# STM32MP21_CA35 register map
File version: 0.4
CPU: CM33 r0p1, little endian, MPU, FPU, vendor SysTick, 8 interrupt priority bits
Registers are 32-bit, read-write, reset 0x0 unless marked. A register's access mark holds for its fields unless they carry their own. Offsets are from the block's base; [hi:lo] are bit positions; {n}, {i} and the like mark numbered series; 'fields as' and 'values as' point back to an identical list.

## HPDMA1 — HPDMA register block
Base 0x40400000
Same registers: HPDMA2 0x40410000, HPDMA3 0x40420000, HPDMA1_S 0x50400000, HPDMA2_S 0x50410000, HPDMA3_S 0x50420000
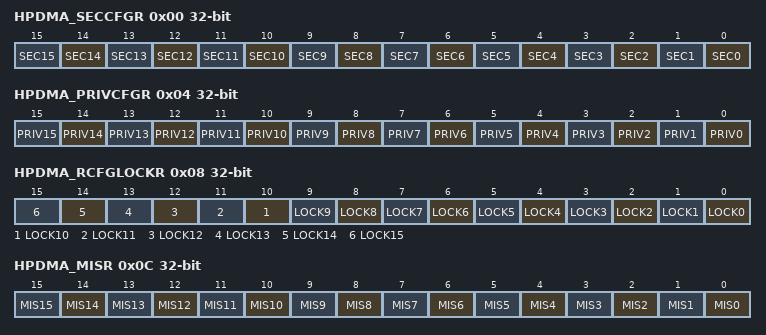
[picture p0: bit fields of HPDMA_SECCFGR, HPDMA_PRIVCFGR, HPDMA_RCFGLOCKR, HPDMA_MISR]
0x00 HPDMA_SECCFGR — HPDMA secure configuration register
  [all] fields
    0=Nonsecure; 1=Secure
  [n] SEC{n} (n=0..15) — Secure state of channel x
0x04 HPDMA_PRIVCFGR — HPDMA privileged configuration register
  [all] fields
    0=Unprivileged; 1=Privileged
  [n] PRIV{n} (n=0..15) — Privileged state of channel x
0x08 HPDMA_RCFGLOCKR — HPDMA configuration lock register
  [all] fields
    0=Secure privilege and CID configuration of the channel x is writable; 1=Secure privilege and CID configuration of the channel x is not writable
  [n] LOCK{n} (n=0..15) — Lock of the configuration of HPDMA_SECCFGR.
0x0C HPDMA_MISR ro — HPDMA nonsecure masked interrupt status register
  [all] fields
    0=No interrupt occurred on channel x; 1=An interrupt occurred on channel x
  [n] MIS{n} (n=0..15) — Masked interrupt status of channel x
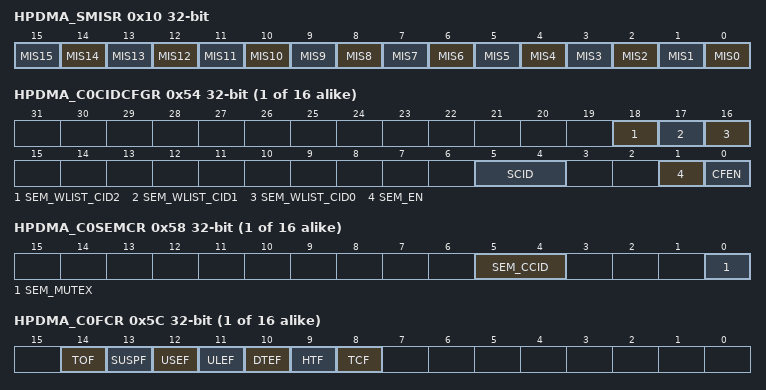
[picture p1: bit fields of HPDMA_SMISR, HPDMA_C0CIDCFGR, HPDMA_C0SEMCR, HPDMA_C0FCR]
0x10 HPDMA_SMISR ro — HPDMA secure masked interrupt status register
  [all] fields
    0=No interrupt occurred on the secure channel x; 1=An interrupt occurred on the secure channel x
  [n] MIS{n} (n=0..15) — Masked interrupt status of the secure channel x
{0x50+0x80*i} HPDMA_C{i}LBAR (i=0..15) — HPDMA channel {i} linked-list base address register
  [31:16] LBA — Linked-list base address of HPDMA channel x
{0x54+0x80*i} HPDMA_C{i}CIDCFGR (i=0..15) — HPDMA channel {i} CID register
  [18] SEM_WLIST_CID2 — White-listed CID2 in the CID allocation pool (for when the channel x
    0=CID2 black-listed in the semaphore-based CID allocation pool; 1=CID2 white-listed in the semaphore-based CID allocation pool
  [17] SEM_WLIST_CID1 — White-listed CID1 in the CID allocation pool (for when the channel x
    0=CID1 black-listed in the semaphore-based CID allocation pool; 1=CID1 white-listed in the semaphore-based CID allocation pool
  [16] SEM_WLIST_CID0 — White-listed CID0 in the CID allocation pool (for when the channel x
    0=CID0 black-listed in the semaphore-based CID allocation pool; 1=CID0 white-listed in the semaphore-based CID allocation pool
  [5:4] SCID — Allocation of a static/single CID to the channel x (for when the channel x CID configuration is not in semaphore mode)
    0=CID0 allocated to the channel x; 1=CID1 allocated to the channel x; 2=CID2 allocated to the channel x
  [1] SEM_EN — Semaphore mode enable (for the CID allocation policy to the channel x)
    0=Semaphore mode disabled; 1=Semaphore mode enabled
  [0] CFEN — CID filtering enable of the channel x
    0=CID filtering disabled for when accessing a channel x register/bit field; 1=CID filtering enabled for when accessing a channel x register/bit field
{0x58+0x80*i} HPDMA_C{i}SEMCR (i=0..15) — HPDMA channel {i} semaphore control register
  [5:4] SEM_CCID ro — Current CID allocated to the channel x (in semaphore mode)
    0=CID0 is the last white-listed CID that took the control of the channel x; 1=CID1 is the last white-listed CID that took the control of the channel x; 2=CID2 is the last white-listed CID that took the control of the channel x
  [0] SEM_MUTEX — Mutual exclusion semaphore for the CID allocation of the channel x
    0=B_0x0_WRITE (Release the control of the channel x (in semaphore mode) to any white-listed CID.); 1=B_0x1_WRITE (Take the control of the channel x (in semaphore mode), from one of the white-listed)
{0x5C+0x80*i} HPDMA_C{i}FCR wo (i=0..15) — HPDMA channel {i} flag clear register
  [14] TOF — Trigger overrun flag clear
    0=No effect; 1=Corresponding TOF flag cleared
  [13] SUSPF — Completed suspension flag clear
    0=No effect; 1=Corresponding SUSPF flag cleared
  [12] USEF — User setting error flag clear
    0=No effect; 1=Corresponding USEF flag cleared
  [11] ULEF — Update link transfer error flag clear
    0=No effect; 1=Corresponding ULEF flag cleared
  [10] DTEF — Data transfer error flag clear
    0=No effect; 1=Corresponding DTEF flag cleared
  [9] HTF — Half transfer flag clear
    0=No effect; 1=Corresponding HTF flag cleared
  [8] TCF — Transfer complete flag clear
    0=No effect; 1=Corresponding TCF flag cleared
{0x60+0x80*i} HPDMA_C{i}SR ro reset 0x1 (i=0..15) — HPDMA channel {i} status register
  [24:16] FIFOL
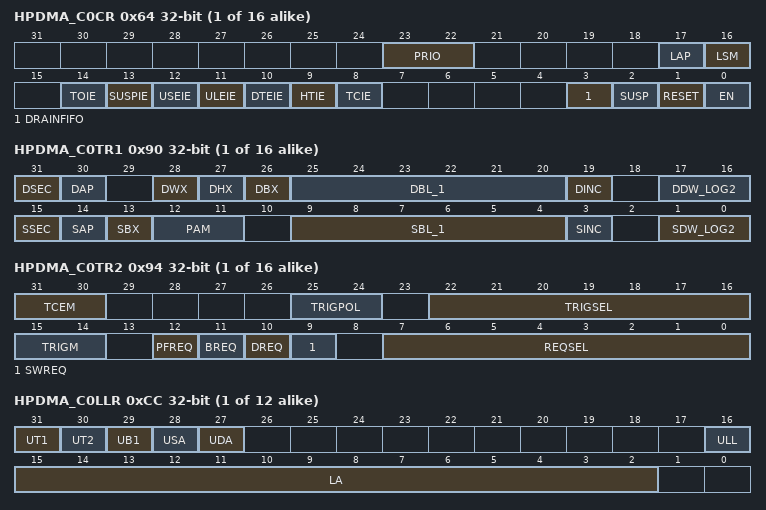
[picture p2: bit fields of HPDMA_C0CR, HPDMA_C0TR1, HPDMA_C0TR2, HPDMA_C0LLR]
{0x64+0x80*i} HPDMA_C{i}CR (i=0..15) — HPDMA channel {i} control register
  [23:22] PRIO — Priority level of the channel x HPDMA transfer versus others
    0=Low priority, low weight; 1=Low priority, mid weight; 2=Low priority, high weight; 3=High priority
  [17] LAP — lLnked-list allocated port
    0=Port 0 (AXI) allocated; 1=Port 1 (AHB) allocated
  [16] LSM — Link step mode
    0=Channel executed for the full linked-list and completed at the end of the last LLI (HPDMA_CxLLR = 0); 1=Channel executed once for the current LLI
  [14] TOIE — Trigger overrun interrupt enable
    0=Interrupt disabled; 1=Interrupt enabled
  [13] SUSPIE — cCmpleted suspension interrupt enable
    0=Interrupt disabled; 1=Interrupt enabled
  [12] USEIE — User setting error interrupt enable
    0=Interrupt disabled; 1=Interrupt enabled
  [11] ULEIE — Update link transfer error interrupt enable
    0=Interrupt disabled; 1=Interrupt enabled
  [10] DTEIE — Data transfer error interrupt enable
    0=Interrupt disabled; 1=Interrupt enabled
  [9] HTIE — Half transfer complete interrupt enable
    0=Interrupt disabled; 1=Interrupt enabled
  [8] TCIE — Transfer complete interrupt enable
    0=Interrupt disabled; 1=Interrupt enabled
  [3] DRAINFIFO wo — Empty FIFO
    0=Write: no action; 1=Write: drain FIFO after having suspended the channel
  [2] SUSP — Suspend
    0=Write: resume channel, read: channel not suspended; 1=Write: suspend channel, read: channel suspended
  [1] RESET wo
    0=No channel reset; 1=Channel reset
  [0] EN — Enable
    0=Write: ignored, read: channel disabled; 1=Write: enable channel, read: channel enabled
{0x90+0x80*i} HPDMA_C{i}TR1 (i=0..15) — HPDMA channel {i} transfer register 1
  [31] DSEC — Security attribute of the HPDMA transfer to the destination
    0=HPDMA transfer nonsecure; 1=HPDMA transfer secure
  [30] DAP — Destination allocated port
    0=Port 0 (AXI) allocated; 1=Port 1 (AHB) allocated
  [28] DWX — Destination word exchange
    0=No word-based exchanged within double-word; 1=The two consecutive (post PAM) words are exchanged in each destination double-word
  [27] DHX — Destination half-word exchange
    0=No half-word-based exchanged within word; 1=The two consecutive (post PAM) half-words are exchanged in each destination word
  [26] DBX — Destination byte exchange
    0=No byte-based exchange within half-word; 1=The two consecutive (post PAM) bytes are exchanged in each destination half-word
  [25:20] DBL_1 — Destination burst length minus 1, between 0 and 63
  [19] DINC — Destination incrementing burst
    0=Fixed burst; 1=Contiguously incremented burst
  [17:16] DDW_LOG2 — Binary logarithm of the destination data width of a burst, in bytes
    0=Byte; 1=Half-word (2 bytes); 2=Word (4 bytes); 3=If DAP = 0 (AXI), double-word (8 bytes)
  [15] SSEC — Security attribute of the HPDMA transfer from the source
    0=HPDMA transfer nonsecure; 1=HPDMA transfer secure
  [14] SAP — Source allocated port
    0=Port 0 (AXI) allocated; 1=Port 1 (AHB) allocated
  [13] SBX — Source byte exchange within the unaligned half-word of each source word
    0=No byte-based exchange within the unaligned half-word of each source word; 1=The two consecutive bytes within the unaligned half-word of each source word
  [12:11] PAM — Padding/alignment mode
    0=B_0x0_PAM_1 (Source data is transferred as right aligned, padded with 0s up to the destination data width); 1=B_0x1_PAM_1 (Source data is transferred as right aligned, sign extended up to the destination data width); 2=B_0x2_PAM_1 (Successive source data are FIFO queued and packed at the destination data width, in a left (LSB) to right (MSB) order (named little endian), before a destination transfer); 3=B_0x3_PAM_1 (Successive source data are FIFO queued and packed at the destination data width, in a left (LSB) to right (MSB) order (named little endian), before a destination transfer)
  [9:4] SBL_1 — Source burst length minus 1, between 0 and 63
  [3] SINC — Source incrementing burst
    0=Fixed burst; 1=Contiguously incremented burst
  [1:0] SDW_LOG2 — Binary logarithm of the source data width of a burst in bytes
    0=Byte; 1=Half-word (2 bytes); 2=Word (4 bytes); 3=If SAP = 0 (AXI), double-word (8 bytes)
{0x94+0x80*i} HPDMA_C{i}TR2 (i=0..15) — HPDMA channel {i} transfer register 2
  [31:30] TCEM — Transfer complete event mode
    0=At block level (when HPDMA_CxBR1; 1=Channel x = 0 to 11, same as 00; channel x = 12 to 15, at 2D/repeated block level; 2=At LLI level: The complete transfer event is generated at the end of the LLI transfer, including the update of the LLI if any; 3=At channel level: The complete transfer event is generated at the end of the last LLI transfer
  [25:24] TRIGPOL — Trigger event polarity
    0=No trigger (masked trigger event); 1=Trigger on the rising edge; 2=Trigger on the falling edge; 3=Same as 00
  [22:16] TRIGSEL — Trigger event input selection
  [15:14] TRIGM — Trigger mode
    0=at block level: the first burst read of each block transfer is conditioned by one hit trigger (channel x = 12 to 15, for each block if a 2D/repeated block is configured with HPDMA_CxBR1; 1=channel x = 0 to 11, same as 00; channel x = 12 to 15, at 2D/repeated block level, the first burst read of a 2D/repeated block transfer is conditioned by one hit trigger; 2=at link level: a LLI link transfer is conditioned by one hit trigger; 3=at programmed burst level: If SWREQ = 1, each programmed burst read is conditioned by one hit trigger
  [12] PFREQ — Hardware request in peripheral flow control mode
    0=The selected hardware request is driven by a peripheral with a hardware request/acknowledge protocol in HPDMA control mode; 1=The selected hardware request is driven by a peripheral with a hardware request/acknowledge protocol in peripheral control mode
  [11] BREQ — Block hardware request
    0=The selected hardware request is driven by a peripheral with a hardware request/acknowledge protocol at a burst level; 1=The selected hardware request is driven by a peripheral with a hardware request/acknowledge protocol at a block level (see Section26
  [10] DREQ — Destination hardware request
    0=Selected hardware request driven by a source peripheral (request signal taken into account by the HPDMA transfer scheduler over the source/read port); 1=Selected hardware request driven by a destination peripheral (request signal taken into account by the HPDMA transfer scheduler over the destination/write port)
  [9] SWREQ — Software request
    0=No software request; 1=Software request for a memory-to-memory transfer
  [7:0] REQSEL — Hardware request selection
{0x98+0x80*i} HPDMA_C{i}BR1 (i=0..11) — HPDMA channel {i} block register 1
  [15:0] BNDT — Block number of data bytes to transfer from the source
{0x9C+0x80*i} HPDMA_C{i}SAR (i=0..15) — HPDMA channel {i} source address register
  [31:0] SA — Source address
{0xA0+0x80*i} HPDMA_C{i}DAR (i=0..15) — HPDMA channel {i} destination address register
  [31:0] DA — destination address
{0xCC+0x80*i} HPDMA_C{i}LLR (i=0..11) — HPDMA channel {i} linked-list address register
  [31] UT1 — Update HPDMA_CxTR1 from memory
    0=No HPDMA_CxTR1 update; 1=HPDMA_CxTR1 update
  [30] UT2 — Update HPDMA_CxTR2 from memory
    0=No HPDMA_CxTR2 update; 1=HPDMA_CxTR2 update
  [29] UB1 — Update HPDMA_CxBR1 from memory
    0=No HPDMA_CxBR1 update from memory (HPDMA_CxBR1; 1=HPDMA_CxBR1 update
  [28] USA — Update HPDMA_CxSAR from memory
    0=No HPDMA_CxSAR update; 1=HPDMA_CxSAR update
  [27] UDA — Update HPDMA_CxDAR register from memory
    0=No HPDMA_CxDAR update; 1=HPDMA_CxDAR update
  [16] ULL — Update HPDMA_CxLLR register from memory
    0=No HPDMA_CxLLR update; 1=HPDMA_CxLLR update
  [15:2] LA — Pointer (16-bit low-significant address) to the next linked-list data structure
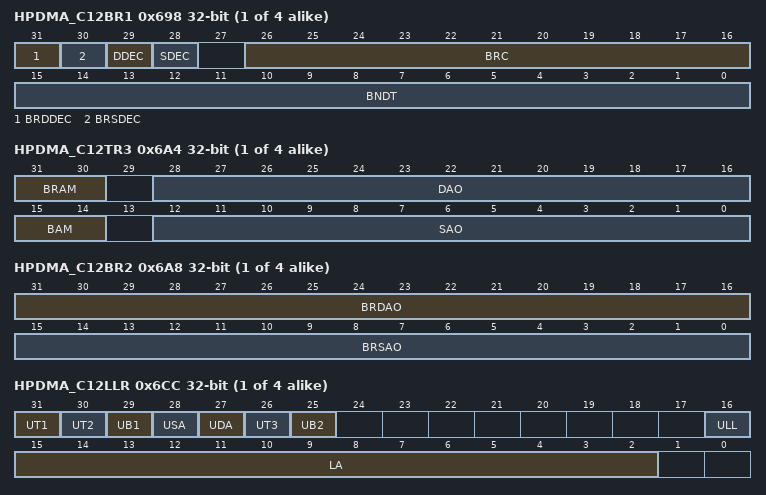
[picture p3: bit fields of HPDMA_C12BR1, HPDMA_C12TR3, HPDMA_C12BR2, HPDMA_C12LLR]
{0x98+0x80*i} HPDMA_C{i}BR1 (i=12..15) — HPDMA channel {i} alternate block register 1
  [31] BRDDEC — Block repeat destination address decrement
    0=At the end of a block transfer, the HPDMA_CxDAR register is updated by adding the programmed offset HPDMA_CxBR2; 1=At the end of a block transfer, the HPDMA_CxDAR register is updated by subtracting the programmed offset HPDMA_CxBR2
  [30] BRSDEC — Block repeat source address decrement
    0=At the end of a block transfer, the HPDMA_CxSAR register is updated by adding the programmed offset HPDMA_CxBR2; 1=At the end of a block transfer, the HPDMA_CxSAR register is updated by subtracting the programmed offset HPDMA_CxBR2
  [29] DDEC — destination address decrement
    0=At the end of a programmed burst transfer to the destination, the HPDMA_CxDAR register is updated by adding the programmed offset HPDMA_CxTR3; 1=At the end of a programmed burst transfer to the destination, the HPDMA_CxDAR register is updated by subtracting the programmed offset HPDMA_CxTR3
  [28] SDEC — source address decrement
    0=At the end of a programmed burst transfer from the source, the HPDMA_CxSAR register is updated by adding the programmed offset HPDMA_CxTR3; 1=At the end of a programmed burst transfer from the source, the HPDMA_CxSAR register is updated by subtracting the programmed offset HPDMA_CxTR3
  [26:16] BRC — Block repeat counter
  [15:0] BNDT — Block number of data bytes to transfer from the source
{0xA4+0x80*i} HPDMA_C{i}TR3 (i=12..15) — HPDMA channel {i} transfer register 3
  [31:30] BRAM — Block repeated alignment mode
    {v}=Repeated block address offset (HPDMA_CxBR2 (v=0..3)
  [28:16] DAO — Destination address offset increment
  [15:14] BAM — Block alignment mode
    0=Block address offset (HPDMA_CxTR3; 1=block address offset (HPDMA_CxTR3; 2=Block address offset (HPDMA_CxTR3; 3=Block address offset (HPDMA_CxTR3
  [12:0] SAO — Source address offset increment
{0xA8+0x80*i} HPDMA_C{i}BR2 (i=12..15) — HPDMA channel {i} block register 2
  [31:16] BRDAO — Block repeated destination address offset
  [15:0] BRSAO — Block repeated source address offset
{0xCC+0x80*i} HPDMA_C{i}LLR (i=12..15) — HPDMA channel {i} alternate linked-list address register
  [31] UT1 — Update HPDMA_CxTR1 from memory
    0=No HPDMA_CxTR1 update; 1=HPDMA_CxTR1 update
  [30] UT2 — Update HPDMA_CxTR2 from memory
    0=No HPDMA_CxTR2 update; 1=HPDMA_CxTR2 update
  [29] UB1 — Update HPDMA_CxBR1 from memory
    values as HPDMA_C0LLR.UB1
  [28] USA — Update HPDMA_CxSAR from memory
    0=No HPDMA_CxSAR update; 1=HPDMA_CxSAR update
  [27] UDA — Update HPDMA_CxDAR register from memory
    0=No HPDMA_CxDAR update; 1=HPDMA_CxDAR update
  [26] UT3 — Update HPDMA_CxTR3 from memory
    0=No HPDMA_CxTR3 update; 1=HPDMA_CxTR3 update
  [25] UB2 — Update HPDMA_CxBR2 from memory
    0=No HPDMA_CxBR2 update; 1=HPDMA_CxBR2 update
  [16] ULL — Update HPDMA_CxLLR register from memory
    0=No HPDMA_CxLLR update; 1=HPDMA_CxLLR update
  [15:2] LA — Pointer (16-bit low-significant address) to the next linked-list data structure
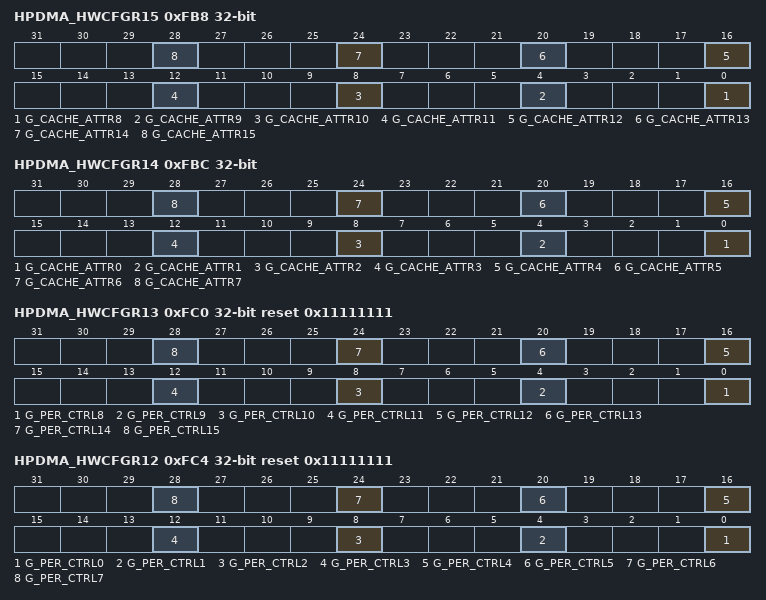
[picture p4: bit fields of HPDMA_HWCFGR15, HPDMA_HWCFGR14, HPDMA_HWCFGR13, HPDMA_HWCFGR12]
0xFB8 HPDMA_HWCFGR15 ro — HPDMA hardware configuration 15 register
  [all] fields
    0=Cache attributes not supported; 1=Cache attributes supported
  [4n-32] G_CACHE_ATTR{n} (n=8..15) — CACHE attributes support for CHANNEL {n}
0xFBC HPDMA_HWCFGR14 ro — HPDMA hardware configuration 14 register
  [all] fields
    values as the fields of HPDMA_HWCFGR15
  [4n] G_CACHE_ATTR{n} (n=0..7) — CACHE attributes support for CHANNEL {n}
0xFC0 HPDMA_HWCFGR13 ro reset 0x11111111 — HPDMA hardware configuration 13 register
  [all] fields
    0=No peripheral flow control mode; 1=Peripheral flow control mode allowed
  [4n-32] G_PER_CTRL{n} (n=8..15) — DMA transfer type for channel {n}
0xFC4 HPDMA_HWCFGR12 ro reset 0x11111111 — HPDMA hardware configuration 12 register
  [all] fields
    values as the fields of HPDMA_HWCFGR13
  [4n] G_PER_CTRL{n} (n=0..7) — DMA transfer type for channel {n}
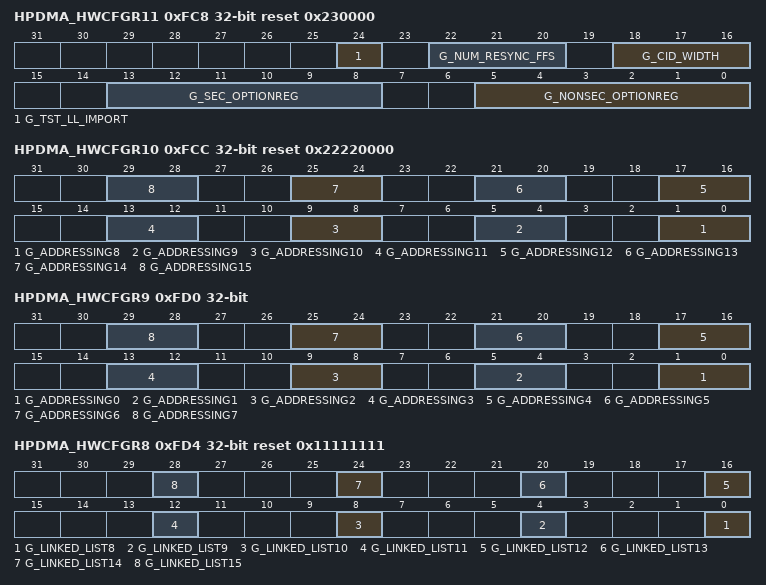
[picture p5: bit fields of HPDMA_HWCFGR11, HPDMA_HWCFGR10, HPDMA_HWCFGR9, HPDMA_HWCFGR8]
0xFC8 HPDMA_HWCFGR11 ro reset 0x230000 — HPDMA hardware configuration 11 register
  [24] G_TST_LL_IMPORT — Master port for the link transfer (DFT purpose only)
    0=Port 0; 1=Port 1
  [22:20] G_NUM_RESYNC_FFS — Number of resynchronization flip-flops, in the range 2 to 6
  [18:16] G_CID_WIDTH — CID bus width, in the range 1 to 4
  [13:8] G_SEC_OPTIONREG — Secure optional register width, in the range 0 to 32
    0=No register
  [5:0] G_NONSEC_OPTIONREG — nonsecure optional register width, in the range 0 to 32
    0=No register
0xFCC HPDMA_HWCFGR10 ro reset 0x22220000 — HPDMA hardware configuration 10 register
  [all] fields
    0=Fixed/contiguous block addressing; 1=Programmable 2D addressing
  [4n-31:4n-32] G_ADDRESSING{n} (n=8..15) — DMA transfer type for channel {n}
0xFD0 HPDMA_HWCFGR9 ro — HPDMA hardware configuration 9 register
  [all] fields
    values as the fields of HPDMA_HWCFGR10
  [4n+1:4n] G_ADDRESSING{n} (n=0..7) — DMA transfer type for channel {n}
0xFD4 HPDMA_HWCFGR8 ro reset 0x11111111 — HPDMA hardware configuration 8 register
  [all] fields
    0=No linked-list mode; 1=Linked-list mode allowed
  [4n-32] G_LINKED_LIST{n} (n=8..15) — DMA transfer type for channel {n}
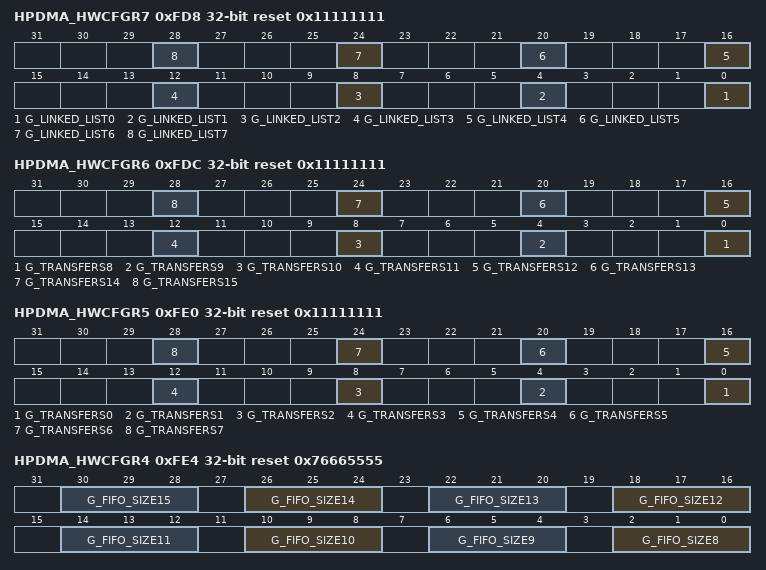
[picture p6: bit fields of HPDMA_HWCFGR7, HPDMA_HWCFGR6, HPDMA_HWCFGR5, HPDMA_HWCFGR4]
0xFD8 HPDMA_HWCFGR7 ro reset 0x11111111 — HPDMA hardware configuration 7 register
  [all] fields
    0=No linked-list mode; 1=Linked-list mode allowed
  [4n] G_LINKED_LIST{n} (n=0..7) — DMA transfer type for channel {n}
0xFDC HPDMA_HWCFGR6 ro reset 0x11111111 — HPDMA hardware configuration 6 register
  [all] fields
    0=Single only; 1=Burst and single
  [4n-32] G_TRANSFERS{n} (n=8..15) — DMA transfer type for channel {n}
0xFE0 HPDMA_HWCFGR5 ro reset 0x11111111 — HPDMA hardware configuration 5 register
  [all] fields
    0=Single only; 1=Burst and single
  [4n] G_TRANSFERS{n} (n=0..7) — DMA transfer type for channel {n}
0xFE4 HPDMA_HWCFGR4 ro reset 0x76665555 — HPDMA hardware configuration 4 register
  [all] fields
    0=No FIFO
  [4n-30:4n-32] G_FIFO_SIZE{n} (n=8..15) — FIFO size for the channel {n}, in the range 0 to 7
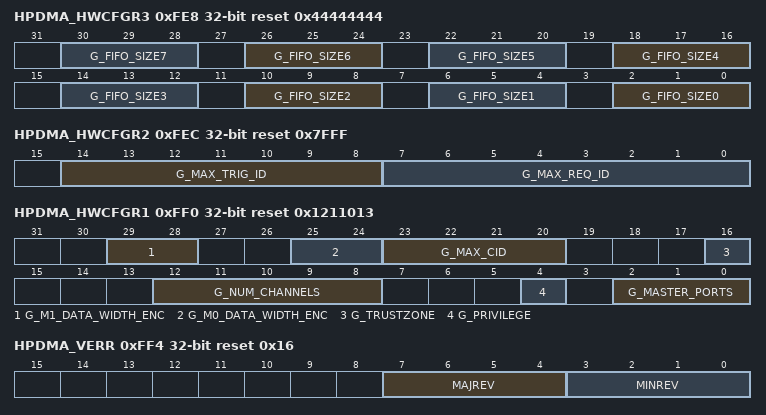
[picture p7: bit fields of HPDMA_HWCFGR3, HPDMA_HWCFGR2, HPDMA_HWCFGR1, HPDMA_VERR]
0xFE8 HPDMA_HWCFGR3 ro reset 0x44444444 — HPDMA hardware configuration 3 register
  [all] fields
    0=No FIFO
  [4n+2:4n] G_FIFO_SIZE{n} (n=0..7) — FIFO size for the channel {n}, in the range 0 to 7
0xFEC HPDMA_HWCFGR2 ro reset 0x7FFF — HPDMA hardware configuration 2 register
  [14:8] G_MAX_TRIG_ID — Maximum trigger event identification (in the range 0 to 127)
  [7:0] G_MAX_REQ_ID — Maximum peripheral request identification (in the range 0 to 255)
0xFF0 HPDMA_HWCFGR1 ro reset 0x1211013 — HPDMA hardware configuration 1 register
  [29:28] G_M1_DATA_WIDTH_ENC — in the range 0 to 2
    0=32-bit; 1=64-bit
  [25:24] G_M0_DATA_WIDTH_ENC — in the range 0 to 2
    0=32-bit; 1=64-bit
  [23:20] G_MAX_CID — in the range 0 to 15
    0=No CID support, HPDMA not CID-aware
  [16] G_TRUSTZONE — TrustZone
    0=No TrustZone; 1=TrustZone support
  [12:8] G_NUM_CHANNELS — in the range 2 to 16
  [4] G_PRIVILEGE — privilege
    0=No privilege; 1=Privilege support
  [2:0] G_MASTER_PORTS — in the range 0 to 5
    0=1x 64-bit AXI (AXI4); 1=1x AHB: 32-bit port 0 (AHB5)
0xFF4 HPDMA_VERR ro reset 0x16 — HPDMA version register
  [7:4] MAJREV — HPDMA major revision
  [3:0] MINREV — HPDMA minor revision
0xFF8 HPDMA_IPIDR ro reset 0x100003 — HPDMA identification register
  [31:0] ID — HPDMA identification
0xFFC HPDMA_SIDR ro reset 0xA3C5DD04 — HPDMA size identification register
  [31:0] SID — size identification
